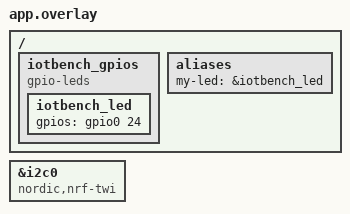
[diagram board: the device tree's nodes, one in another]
&i2c0 {
	compatible = "nordic,nrf-twi";
};

/ {
	iotbench_gpios {
		compatible = "gpio-leds";
		iotbench_led: iotbench_led {
			gpios = <&gpio0 24 GPIO_ACTIVE_HIGH>;
		};
	};
	aliases {
		my-led = &iotbench_led;
	};
};
